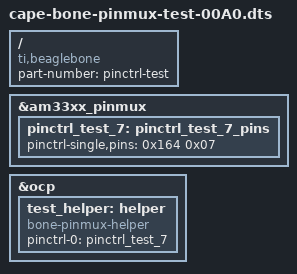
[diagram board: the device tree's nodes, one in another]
/*
 * Copyright (C) 2012 Texas Instruments Incorporated - http://www.ti.com/
 *
 * This program is free software; you can redistribute it and/or modify
 * it under the terms of the GNU General Public License version 2 as
 * published by the Free Software Foundation.
 */
/dts-v1/;
/plugin/;

/ {
	compatible = "ti,beaglebone", "ti,beaglebone-black", "ti,beaglebone-green";

	/* identification */
	part-number = "pinctrl-test";

	fragment@0 {
		target = <&am33xx_pinmux>;
		__overlay__ {
			pinctrl_test_7: pinctrl_test_7_pins {
				pinctrl-single,pins = <
					0x164 0x07	/* P9_42 muxRegOffset, OUTPUT | MODE7 */
				>;
			};
		};
	};

	fragment@1 {
		target = <&ocp>;
		__overlay__ {
			/* avoid stupid warning */
			#address-cells = <1>;
			#size-cells = <1>;

			test_helper: helper {
				compatible = "bone-pinmux-helper";
				pinctrl-names = "default";
				pinctrl-0 = <&pinctrl_test_7>;
				status = "okay";
			};
		};
	};
};
